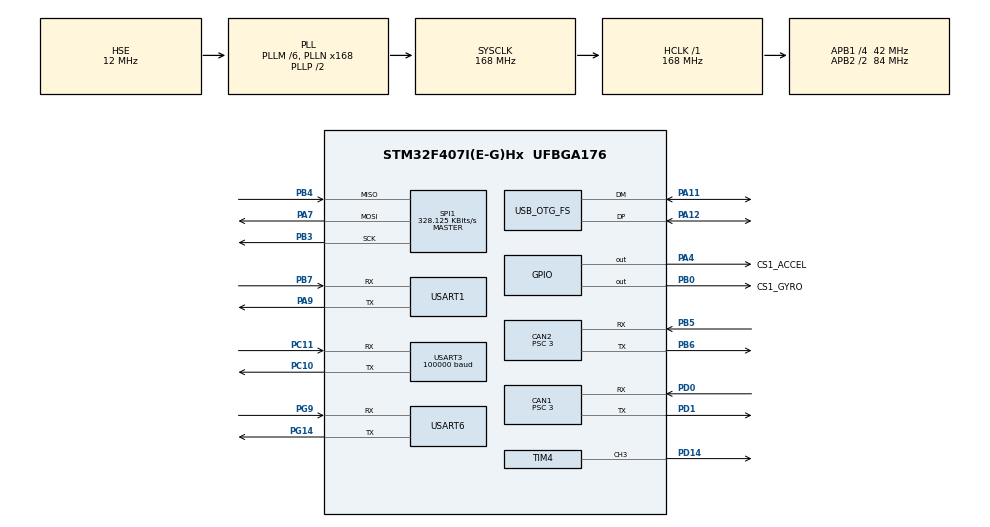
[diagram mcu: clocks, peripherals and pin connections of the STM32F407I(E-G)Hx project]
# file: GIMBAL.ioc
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CAN1.BS1=CAN_BS1_12TQ
CAN1.CalculateBaudRate=1000000
CAN1.CalculateTimeBit=1000
CAN1.CalculateTimeQuantum=71.42857142857143
CAN1.NART=ENABLE
CAN1.Prescaler=3
CAN2.BS1=CAN_BS1_12TQ
CAN2.CalculateBaudRate=1000000
CAN2.CalculateTimeBit=1000
CAN2.CalculateTimeQuantum=71.42857142857143
CAN2.Prescaler=3
Dma.Request0=SPI1_RX
Dma.Request1=SPI1_TX
Dma.Request2=USART3_RX
Dma.Request3=USART6_RX
Dma.Request4=USART6_TX
Dma.SPI1_RX.0.Direction=DMA_PERIPH_TO_MEMORY
Dma.SPI1_RX.0.FIFOMode=DMA_FIFOMODE_DISABLE
Dma.SPI1_RX.0.Instance=DMA2_Stream2
Dma.SPI1_RX.0.MemDataAlignment=DMA_MDATAALIGN_BYTE
Dma.SPI1_RX.0.MemInc=DMA_MINC_ENABLE
Dma.SPI1_RX.0.Mode=DMA_NORMAL
Dma.SPI1_RX.0.PeriphDataAlignment=DMA_PDATAALIGN_BYTE
Dma.SPI1_RX.0.PeriphInc=DMA_PINC_DISABLE
Dma.SPI1_RX.0.Priority=DMA_PRIORITY_LOW
Dma.SPI1_TX.1.Direction=DMA_MEMORY_TO_PERIPH
Dma.SPI1_TX.1.FIFOMode=DMA_FIFOMODE_DISABLE
Dma.SPI1_TX.1.Instance=DMA2_Stream3
Dma.SPI1_TX.1.MemDataAlignment=DMA_MDATAALIGN_BYTE
Dma.SPI1_TX.1.MemInc=DMA_MINC_ENABLE
Dma.SPI1_TX.1.Mode=DMA_NORMAL
Dma.SPI1_TX.1.PeriphDataAlignment=DMA_PDATAALIGN_BYTE
Dma.SPI1_TX.1.PeriphInc=DMA_PINC_DISABLE
Dma.SPI1_TX.1.Priority=DMA_PRIORITY_LOW
Dma.USART3_RX.2.Direction=DMA_PERIPH_TO_MEMORY
Dma.USART3_RX.2.FIFOMode=DMA_FIFOMODE_DISABLE
Dma.USART3_RX.2.Instance=DMA1_Stream1
Dma.USART3_RX.2.MemDataAlignment=DMA_MDATAALIGN_BYTE
Dma.USART3_RX.2.MemInc=DMA_MINC_ENABLE
Dma.USART3_RX.2.Mode=DMA_NORMAL
Dma.USART3_RX.2.PeriphDataAlignment=DMA_PDATAALIGN_BYTE
Dma.USART3_RX.2.PeriphInc=DMA_PINC_DISABLE
Dma.USART3_RX.2.Priority=DMA_PRIORITY_LOW
Dma.USART6_RX.3.Direction=DMA_PERIPH_TO_MEMORY
Dma.USART6_RX.3.FIFOMode=DMA_FIFOMODE_DISABLE
Dma.USART6_RX.3.Instance=DMA2_Stream1
Dma.USART6_RX.3.MemDataAlignment=DMA_MDATAALIGN_BYTE
Dma.USART6_RX.3.MemInc=DMA_MINC_ENABLE
Dma.USART6_RX.3.Mode=DMA_NORMAL
Dma.USART6_RX.3.PeriphDataAlignment=DMA_PDATAALIGN_BYTE
Dma.USART6_RX.3.PeriphInc=DMA_PINC_DISABLE
Dma.USART6_RX.3.Priority=DMA_PRIORITY_LOW
Dma.USART6_TX.4.Direction=DMA_MEMORY_TO_PERIPH
Dma.USART6_TX.4.FIFOMode=DMA_FIFOMODE_DISABLE
Dma.USART6_TX.4.Instance=DMA2_Stream6
Dma.USART6_TX.4.MemDataAlignment=DMA_MDATAALIGN_BYTE
Dma.USART6_TX.4.MemInc=DMA_MINC_ENABLE
Dma.USART6_TX.4.Mode=DMA_NORMAL
Dma.USART6_TX.4.PeriphDataAlignment=DMA_PDATAALIGN_BYTE
Dma.USART6_TX.4.PeriphInc=DMA_PINC_DISABLE
Dma.USART6_TX.4.Priority=DMA_PRIORITY_LOW
FREERTOS.Tasks01=INS_TASK,3,1024,INS_task,As weak,NULL,Dynamic,NULL,NULL;GIMBAL_TASK,0,256,gimbal_task,As weak,NULL,Dynamic,NULL,NULL;DETECT_TASK,-1,128,detect_task,As weak,NULL,Dynamic,NULL,NULL;SHOOT_TASK,0,128,shoot_task,As weak,NULL,Dynamic,NULL,NULL;VOFA_TASK,-3,128,vofa_task,As weak,NULL,Dynamic,NULL,NULL;AIMBOTS_TASK,0,128,aimbots_task,As weak,NULL,Dynamic,NULL,NULL;COMMUNICATE_TAS,1,256,communicate_task,As weak,NULL,Dynamic,NULL,NULL;KEY_TASK,-2,128,key_task,As weak,NULL,Dynamic,NULL,NULL
Mcu.Family=STM32F4
Mcu.Name=STM32F407I(E-G)Hx
Mcu.Package=UFBGA176
NVIC.CAN1_RX0_IRQn=true\:5\:0\:false\:false\:true\:true\:true\:true\:true
NVIC.CAN1_RX1_IRQn=true\:5\:0\:false\:false\:true\:true\:true\:true\:true
NVIC.CAN1_TX_IRQn=true\:5\:0\:false\:false\:true\:true\:true\:true\:true
NVIC.CAN2_RX0_IRQn=true\:5\:0\:false\:false\:true\:true\:true\:true\:true
NVIC.CAN2_RX1_IRQn=true\:5\:0\:false\:false\:true\:true\:true\:true\:true
NVIC.DMA1_Stream1_IRQn=true\:5\:0\:false\:false\:true\:true\:false\:true\:true
NVIC.DMA2_Stream1_IRQn=true\:5\:0\:false\:false\:true\:true\:false\:true\:true
NVIC.DMA2_Stream2_IRQn=true\:5\:0\:false\:false\:true\:false\:false\:true\:true
NVIC.DMA2_Stream3_IRQn=true\:5\:0\:false\:false\:true\:true\:false\:true\:true
NVIC.DMA2_Stream6_IRQn=true\:5\:0\:false\:false\:true\:true\:false\:true\:true
NVIC.OTG_FS_IRQn=true\:5\:0\:false\:false\:true\:true\:false\:true\:true
NVIC.PriorityGroup=NVIC_PRIORITYGROUP_4
NVIC.TIM5_IRQn=true\:15\:0\:false\:false\:true\:false\:false\:true\:true
NVIC.TimeBase=TIM5_IRQn
NVIC.TimeBaseIP=TIM5
NVIC.USART1_IRQn=true\:5\:0\:false\:false\:true\:true\:true\:true\:true
NVIC.USART3_IRQn=true\:5\:0\:false\:false\:true\:true\:true\:true\:true
NVIC.USART6_IRQn=true\:5\:0\:false\:false\:true\:true\:true\:true\:true
PA11.Mode=Device_Only
PA11.Signal=USB_OTG_FS_DM
PA12.Mode=Device_Only
PA12.Signal=USB_OTG_FS_DP
PA13.Mode=Serial_Wire
PA13.Signal=SYS_JTMS-SWDIO
PA14.Mode=Serial_Wire
PA14.Signal=SYS_JTCK-SWCLK
PA4.GPIO_Label=CS1_ACCEL
PA4.GPIO_Speed=GPIO_SPEED_FREQ_HIGH
PA4.Signal=GPIO_Output
PA7.Mode=Full_Duplex_Master
PA7.Signal=SPI1_MOSI
PA9.Mode=Asynchronous
PA9.Signal=USART1_TX
PB0.GPIO_Label=CS1_GYRO
PB0.GPIO_Speed=GPIO_SPEED_FREQ_HIGH
PB0.Signal=GPIO_Output
PB3.Mode=Full_Duplex_Master
PB3.Signal=SPI1_SCK
PB4.Mode=Full_Duplex_Master
PB4.Signal=SPI1_MISO
PB5.Mode=CAN_Activate
PB5.Signal=CAN2_RX
PB6.Mode=CAN_Activate
PB6.Signal=CAN2_TX
PB7.Mode=Asynchronous
PB7.Signal=USART1_RX
PC10.Mode=Asynchronous
PC10.Signal=USART3_TX
PC11.Mode=Asynchronous
PC11.Signal=USART3_RX
PD0.Mode=CAN_Activate
PD0.Signal=CAN1_RX
PD1.Mode=CAN_Activate
PD1.Signal=CAN1_TX
PD14.Signal=S_TIM4_CH3
PG14.Mode=Asynchronous
PG14.Signal=USART6_TX
PG9.Mode=Asynchronous
PG9.Signal=USART6_RX
PH0-OSC_IN.Mode=HSE-External-Oscillator
PH0-OSC_IN.Signal=RCC_OSC_IN
PH1-OSC_OUT.Mode=HSE-External-Oscillator
PH1-OSC_OUT.Signal=RCC_OSC_OUT
ProjectManager.HeapSize=0x200
ProjectManager.StackSize=0x400
ProjectManager.TargetToolchain=MDK-ARM V5.32
RCC.48MHZClocksFreq_Value=48000000
RCC.AHBFreq_Value=168000000
RCC.APB1CLKDivider=RCC_HCLK_DIV4
RCC.APB1Freq_Value=42000000
RCC.APB1TimFreq_Value=84000000
RCC.APB2CLKDivider=RCC_HCLK_DIV2
RCC.APB2Freq_Value=84000000
RCC.APB2TimFreq_Value=168000000
RCC.CortexFreq_Value=168000000
RCC.HCLKFreq_Value=168000000
RCC.HSE_VALUE=12000000
RCC.HSI_VALUE=16000000
RCC.LSE_VALUE=32768
RCC.PLLM=6
RCC.PLLN=168
RCC.PLLQ=7
RCC.SYSCLKFreq_VALUE=168000000
RCC.SYSCLKSource=RCC_SYSCLKSOURCE_PLLCLK
RCC.VCOOutputFreq_Value=336000000
SH.S_TIM4_CH3.0=TIM4_CH3,PWM Generation3 CH3
SPI1.BaudRatePrescaler=SPI_BAUDRATEPRESCALER_256
SPI1.CLKPhase=SPI_PHASE_2EDGE
SPI1.CLKPolarity=SPI_POLARITY_HIGH
SPI1.CalculateBaudRate=328.125 KBits/s
SPI1.Direction=SPI_DIRECTION_2LINES
SPI1.Mode=SPI_MODE_MASTER
SPI1.VirtualType=VM_MASTER
TIM4.Channel-PWM\ Generation3\ CH3=TIM_CHANNEL_3
TIM4.OCPolarity_3=TIM_OCPOLARITY_HIGH
TIM4.Period=20999
USART1.VirtualMode=VM_ASYNC
USART3.BaudRate=100000
USART3.VirtualMode=VM_ASYNC
USART6.VirtualMode=VM_ASYNC
USB_DEVICE.CLASS_NAME_FS=CDC
USB_DEVICE.VirtualMode-CDC_FS=Cdc
USB_DEVICE.VirtualModeFS=Cdc_FS
USB_OTG_FS.VirtualMode=Device_Only
VP_FREERTOS_VS_CMSIS_V1.Mode=CMSIS_V1
VP_SYS_VS_tim5.Mode=TIM5
VP_TIM4_VS_ClockSourceINT.Mode=Internal
VP_USB_DEVICE_VS_USB_DEVICE_CDC_FS.Mode=CDC_FS
board=custom

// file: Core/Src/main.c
/* USER CODE BEGIN Header */
/**
  ******************************************************************************
  * @file           : main.c
  * @brief          : Main program body
  ******************************************************************************
  * @attention
  *
  * Copyright (c) 2025 STMicroelectronics.
  * All rights reserved.
  *
  * This software is licensed under terms that can be found in the LICENSE file
  * in the root directory of this software component.
  * If no LICENSE file comes with this software, it is provided AS-IS.
  *
  ******************************************************************************
  */
/* USER CODE END Header */
#include "main.h"
#include "cmsis_os.h"
#include "can.h"
#include "dma.h"
#include "spi.h"
#include "tim.h"
#include "usart.h"
#include "usb_device.h"
#include "gpio.h"

/* USER CODE BEGIN Includes */
#include "Can_receive.h"
#include "pid.h"
#include "remote_control.h"
#include "bsp_buzzer.h"
#include "usb_device.h"
#include "event_groups.h"
/* USER CODE END Includes */

void SystemClock_Config(void);
void MX_FREERTOS_Init(void);

int main(void)
{

  /* MCU Configuration--------------------------------------------------------*/

  /* Reset of all peripherals, Initializes the Flash interface and the Systick. */
  HAL_Init();

  /* Configure the system clock */
  SystemClock_Config();

  /* Initialize all configured peripherals */
  MX_GPIO_Init();
  MX_DMA_Init();
  MX_CAN1_Init();
  MX_CAN2_Init();
  MX_SPI1_Init();
  MX_TIM4_Init();
  MX_USART1_UART_Init();
  MX_USART3_UART_Init();
  MX_USART6_UART_Init();
  /* USER CODE BEGIN 2 */
	MX_USB_DEVICE_Init();
	remote_control_init();
	Buzzer_Init();
	canfilter_init_start();

  /* USER CODE END 2 */

  /* Call init function for freertos objects (in freertos.c) */
  MX_FREERTOS_Init();

  /* Start scheduler */
  osKernelStart();

  /* We should never get here as control is now taken by the scheduler */
  /* Infinite loop */
  while (1)
  {

  }
}

void SystemClock_Config(void)
{
  RCC_OscInitTypeDef RCC_OscInitStruct = {0};
  RCC_ClkInitTypeDef RCC_ClkInitStruct = {0};

  /** Configure the main internal regulator output voltage
  */
  __HAL_RCC_PWR_CLK_ENABLE();
  __HAL_PWR_VOLTAGESCALING_CONFIG(PWR_REGULATOR_VOLTAGE_SCALE1);

  /** Initializes the RCC Oscillators according to the specified parameters
  * in the RCC_OscInitTypeDef structure.
  */
  RCC_OscInitStruct.OscillatorType = RCC_OSCILLATORTYPE_HSE;
  RCC_OscInitStruct.HSEState = RCC_HSE_ON;
  RCC_OscInitStruct.PLL.PLLState = RCC_PLL_ON;
  RCC_OscInitStruct.PLL.PLLSource = RCC_PLLSOURCE_HSE;
  RCC_OscInitStruct.PLL.PLLM = 6;
  RCC_OscInitStruct.PLL.PLLN = 168;
  RCC_OscInitStruct.PLL.PLLP = RCC_PLLP_DIV2;
  RCC_OscInitStruct.PLL.PLLQ = 7;
  if (HAL_RCC_OscConfig(&RCC_OscInitStruct) != HAL_OK)
  {
    Error_Handler();
  }

  /** Initializes the CPU, AHB and APB buses clocks
  */
  RCC_ClkInitStruct.ClockType = RCC_CLOCKTYPE_HCLK|RCC_CLOCKTYPE_SYSCLK
                              |RCC_CLOCKTYPE_PCLK1|RCC_CLOCKTYPE_PCLK2;
  RCC_ClkInitStruct.SYSCLKSource = RCC_SYSCLKSOURCE_PLLCLK;
  RCC_ClkInitStruct.AHBCLKDivider = RCC_SYSCLK_DIV1;
  RCC_ClkInitStruct.APB1CLKDivider = RCC_HCLK_DIV4;
  RCC_ClkInitStruct.APB2CLKDivider = RCC_HCLK_DIV2;

  if (HAL_RCC_ClockConfig(&RCC_ClkInitStruct, FLASH_LATENCY_5) != HAL_OK)
  {
    Error_Handler();
  }
}

void HAL_TIM_PeriodElapsedCallback(TIM_HandleTypeDef *htim)
{
  if (htim->Instance == TIM5) {
    HAL_IncTick();
  }
}

void Error_Handler(void)
{
  __disable_irq();
  while (1)
  {
  }
}

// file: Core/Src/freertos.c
/* USER CODE BEGIN Header */
/**
  ******************************************************************************
  * File Name          : freertos.c
  * Description        : Code for freertos applications
  ******************************************************************************
  * @attention
  *
  * Copyright (c) 2025 STMicroelectronics.
  * All rights reserved.
  *
  * This software is licensed under terms that can be found in the LICENSE file
  * in the root directory of this software component.
  * If no LICENSE file comes with this software, it is provided AS-IS.
  *
  ******************************************************************************
  */
/* USER CODE END Header */

#include "FreeRTOS.h"
#include "task.h"
#include "main.h"
#include "cmsis_os.h"

osThreadId INS_TASKHandle;
osThreadId GIMBAL_TASKHandle;
osThreadId DETECT_TASKHandle;
osThreadId SHOOT_TASKHandle;
osThreadId VOFA_TASKHandle;
osThreadId COMMUNICATE_TASHandle;
osThreadId KEY_TASKHandle;
osThreadId BUZZER_TASKHandle;

void INS_task(void const * argument);
void gimbal_task(void const * argument);
void detect_task(void const * argument);
void shoot_task(void const * argument);
void vofa_task(void const * argument);
void communicate_task(void const * argument);
void key_task(void const * argument);
void buzzer_effects_task(void const *argument);

extern void MX_USB_DEVICE_Init(void);
void MX_FREERTOS_Init(void); /* (MISRA C 2004 rule 8.1) */

/* GetIdleTaskMemory prototype (linked to static allocation support) */
void vApplicationGetIdleTaskMemory( StaticTask_t **ppxIdleTaskTCBBuffer, StackType_t **ppxIdleTaskStackBuffer, uint32_t *pulIdleTaskStackSize );

/* USER CODE BEGIN GET_IDLE_TASK_MEMORY */
static StaticTask_t xIdleTaskTCBBuffer;
static StackType_t xIdleStack[configMINIMAL_STACK_SIZE];

void vApplicationGetIdleTaskMemory( StaticTask_t **ppxIdleTaskTCBBuffer, StackType_t **ppxIdleTaskStackBuffer, uint32_t *pulIdleTaskStackSize )
{
  *ppxIdleTaskTCBBuffer = &xIdleTaskTCBBuffer;
  *ppxIdleTaskStackBuffer = &xIdleStack[0];
  *pulIdleTaskStackSize = configMINIMAL_STACK_SIZE;
  /* place for user code */
}
/* USER CODE END GET_IDLE_TASK_MEMORY */

void MX_FREERTOS_Init(void) {

  /* Create the thread(s) */
  /* definition and creation of INS_TASK */
  osThreadDef(INS_TASK, INS_task, osPriorityRealtime, 0, 1024);
  INS_TASKHandle = osThreadCreate(osThread(INS_TASK), NULL);

  /* definition and creation of GIMBAL_TASK */
  osThreadDef(GIMBAL_TASK, gimbal_task, osPriorityNormal, 0, 256);
  GIMBAL_TASKHandle = osThreadCreate(osThread(GIMBAL_TASK), NULL);

  /* definition and creation of DETECT_TASK */
  osThreadDef(DETECT_TASK, detect_task, osPriorityBelowNormal, 0, 128);
  DETECT_TASKHandle = osThreadCreate(osThread(DETECT_TASK), NULL);

  /* definition and creation of SHOOT_TASK */
  osThreadDef(SHOOT_TASK, shoot_task, osPriorityNormal, 0, 128);
  SHOOT_TASKHandle = osThreadCreate(osThread(SHOOT_TASK), NULL);

  /* definition and creation of VOFA_TASK */
  osThreadDef(VOFA_TASK, vofa_task, osPriorityIdle, 0, 128);
  VOFA_TASKHandle = osThreadCreate(osThread(VOFA_TASK), NULL);

  /* definition and creation of COMMUNICATE_TAS */
  osThreadDef(COMMUNICATE_TAS, communicate_task, osPriorityAboveNormal, 0, 256);
  COMMUNICATE_TASHandle = osThreadCreate(osThread(COMMUNICATE_TAS), NULL);

  /* definition and creation of KEY_TASK */
  osThreadDef(KEY_TASK, key_task, osPriorityLow, 0, 128);
  KEY_TASKHandle = osThreadCreate(osThread(KEY_TASK), NULL);

  osThreadDef(BUZZER_EFFECTS_TASK, buzzer_effects_task, osPriorityLow, 0, 128);
  BUZZER_TASKHandle = osThreadCreate(osThread(BUZZER_EFFECTS_TASK), NULL);

}

__weak void INS_task(void const * argument)
{
  /* init code for USB_DEVICE */
  MX_USB_DEVICE_Init();
  for(;;)
  {
    osDelay(1);
  }
}

__weak void gimbal_task(void const * argument)
{
  for(;;)
  {
    osDelay(1);
  }
}

__weak void detect_task(void const * argument)
{
  for(;;)
  {
    osDelay(1);
  }
}

__weak void shoot_task(void const * argument)
{
  for(;;)
  {
    osDelay(1);
  }
}

__weak void vofa_task(void const * argument)
{
  for(;;)
  {
    osDelay(1);
  }
}

__weak void communicate_task(void const * argument)
{
  for(;;)
  {
    osDelay(1);
  }
}

__weak void key_task(void const * argument)
{
  for(;;)
  {
    osDelay(1);
  }
}

__weak void buzzer_effects_task(void const * argument)
{
	for(;;)
	osDelay(1);
}
